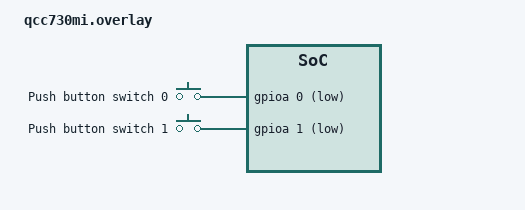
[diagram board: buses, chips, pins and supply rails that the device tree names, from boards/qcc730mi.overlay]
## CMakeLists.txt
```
# Copyright (c) Qualcomm Technologies, Inc. and/or its subsidiaries.
# SPDX-License-Identifier: BSD-3-Clause-Clear

cmake_minimum_required(VERSION 3.20.0)
find_package(Zephyr REQUIRED HINTS $ENV{ZEPHYR_BASE})
project(buttons)

target_sources(app PRIVATE src/main.c)
```

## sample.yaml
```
# Copyright (c) Qualcomm Technologies, Inc. and/or its subsidiaries.
# SPDX-License-Identifier: BSD-3-Clause-Clear

sample:
  name: Buttons Sample
tests:
  sample.buttons:
    tags:
      - button
      - gpio
    filter: dt_enabled_alias_with_parent_compat("sw0", "gpio-keys") and dt_enabled_alias_with_parent_compat("sw1", "gpio-keys")
    depends_on: gpio
    harness: button
```

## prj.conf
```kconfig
# Copyright (c) Qualcomm Technologies, Inc. and/or its subsidiaries.
# SPDX-License-Identifier: BSD-3-Clause-Clear

CONFIG_GPIO=y
```

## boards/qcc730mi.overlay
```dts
/*
 * Copyright (c) Qualcomm Technologies, Inc. and/or its subsidiaries.
 *
 * SPDX-License-Identifier: BSD-3-Clause-Clear
 */

#include <zephyr/dt-bindings/input/input-event-codes.h>

/ {
	buttons {
		compatible = "gpio-keys";
		button0: button_0 {
			gpios = <&gpioa 0 (GPIO_PULL_UP | GPIO_ACTIVE_LOW)>;
			label = "Push button switch 0";
			zephyr,code = <INPUT_KEY_0>;
		};

		button1: button_1 {
			gpios = <&gpioa 1 (GPIO_PULL_UP | GPIO_ACTIVE_LOW)>;
			label = "Push button switch 1";
			zephyr,code = <INPUT_KEY_1>;
		};
	};

	aliases {
		sw0 = &button0;
		sw1 = &button1;
	};
};

&gpioa {
	status = "okay";
};
```

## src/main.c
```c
/*
 * Copyright (c) Qualcomm Technologies, Inc. and/or its subsidiaries.
 *
 * SPDX-License-Identifier: BSD-3-Clause-Clear
 */

#include <zephyr/kernel.h>
#include <zephyr/device.h>
#include <zephyr/drivers/gpio.h>
#include <zephyr/sys/util.h>
#include <zephyr/sys/printk.h>
#include <inttypes.h>

#define SLEEP_MS 1

/*
 * Get button configuration from the devicetree sw0 and sw1 aliases. This is mandatory.
 */
#define SW0_NODE DT_ALIAS(sw0)
#if !DT_NODE_HAS_STATUS_OKAY(SW0_NODE)
#error "Unsupported board: sw0 devicetree alias is not defined"
#endif
static const struct gpio_dt_spec button0 = GPIO_DT_SPEC_GET_OR(SW0_NODE, gpios, {0});

#define SW1_NODE DT_ALIAS(sw1)
#if !DT_NODE_HAS_STATUS_OKAY(SW1_NODE)
#error "Unsupported board: sw1 devicetree alias is not defined"
#endif
static const struct gpio_dt_spec button1 = GPIO_DT_SPEC_GET_OR(SW1_NODE, gpios, {0});

static struct gpio_callback button0_cb_data;
static struct gpio_callback button1_cb_data;

void button0_pressed(const struct device *dev, struct gpio_callback *cb, uint32_t pins)
{
	printk("Button0 pressed at %" PRIu32 "\n", k_cycle_get_32());
}

void button1_pressed(const struct device *dev, struct gpio_callback *cb, uint32_t pins)
{
	printk("Button1 pressed at %" PRIu32 "\n", k_cycle_get_32());
}

int main(void)
{
	int ret;

	if (!gpio_is_ready_dt(&button0)) {
		printk("Error: button0 device %s is not ready\n", button0.port->name);
		return 0;
	}

	if (!gpio_is_ready_dt(&button1)) {
		printk("Error: button1 device %s is not ready\n", button1.port->name);
		return 0;
	}

	ret = gpio_pin_configure_dt(&button0, GPIO_INPUT);
	if (ret != 0) {
		printk("Error %d: failed to configure %s pin %d\n", ret, button0.port->name,
		       button0.pin);
		return 0;
	}

	ret = gpio_pin_configure_dt(&button1, GPIO_INPUT);
	if (ret != 0) {
		printk("Error %d: failed to configure %s pin %d\n", ret, button1.port->name,
		       button1.pin);
		return 0;
	}

	ret = gpio_pin_interrupt_configure_dt(&button0, GPIO_INT_EDGE_TO_ACTIVE);
	if (ret != 0) {
		printk("Error %d: failed to configure interrupt on %s pin %d\n", ret,
		       button0.port->name, button0.pin);
		return 0;
	}

	ret = gpio_pin_interrupt_configure_dt(&button1, GPIO_INT_EDGE_TO_ACTIVE);
	if (ret != 0) {
		printk("Error %d: failed to configure interrupt on %s pin %d\n", ret,
		       button1.port->name, button1.pin);
		return 0;
	}

	gpio_init_callback(&button0_cb_data, button0_pressed, BIT(button0.pin));
	gpio_add_callback(button0.port, &button0_cb_data);
	printk("Set up button at %s pin %d\n", button0.port->name, button0.pin);

	gpio_init_callback(&button1_cb_data, button1_pressed, BIT(button1.pin));
	gpio_add_callback(button1.port, &button1_cb_data);
	printk("Set up button at %s pin %d\n", button1.port->name, button1.pin);

	printk("Press any button\n");
	while (1) {
		k_msleep(SLEEP_MS);
	}

	return 0;
}
```
